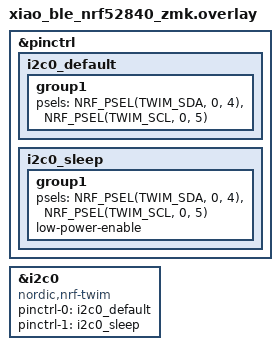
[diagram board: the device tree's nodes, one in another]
#include <dt-bindings/pinctrl/nrf-pinctrl.h>

&pinctrl {
    i2c0_default: i2c0_default {
        group1 {
            psels = <NRF_PSEL(TWIM_SDA, 0, 4)>,
                    <NRF_PSEL(TWIM_SCL, 0, 5)>;
        };
    };

    i2c0_sleep: i2c0_sleep {
        group1 {
            psels = <NRF_PSEL(TWIM_SDA, 0, 4)>,
                    <NRF_PSEL(TWIM_SCL, 0, 5)>;
            low-power-enable;
        };
    };
};

&i2c0 {
    compatible = "nordic,nrf-twim";
    pinctrl-0 = <&i2c0_default>;
    pinctrl-1 = <&i2c0_sleep>;
    pinctrl-names = "default", "sleep";
};
